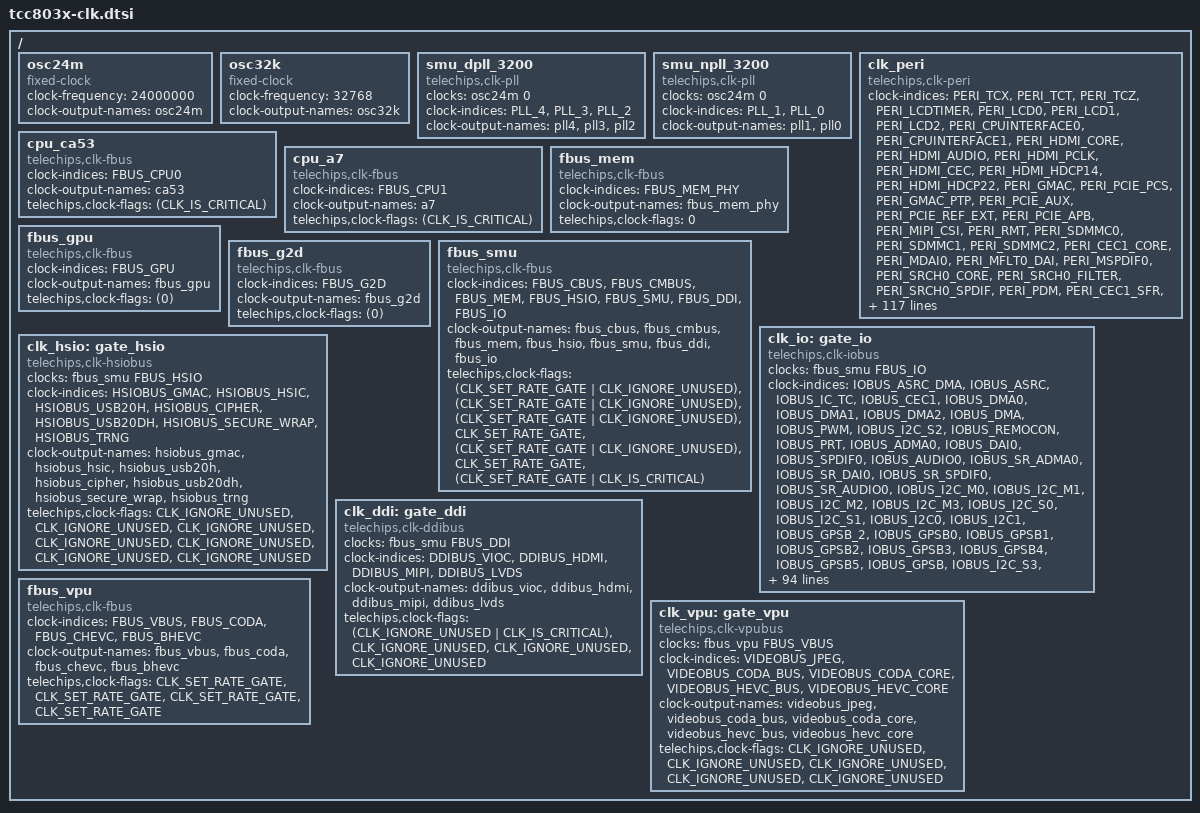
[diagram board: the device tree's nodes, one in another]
// SPDX-License-Identifier: (GPL-2.0-or-later OR MIT)
/*
 * Copyright (C) 2023 Telechips Inc.
 */

#include <dt-bindings/clock/telechips,tcc803x-clks.h>

/ {
	osc24m: osc24m {
		compatible = "fixed-clock";
		#clock-cells = <1>;
		clock-frequency = <24000000>;
		clock-output-names = "osc24m";
	};

	osc32k: osc32k {
		compatible = "fixed-clock";
		#clock-cells = <1>;
		clock-frequency = <32768>;
		clock-output-names = "osc32k";
	};

	smu_dpll_3200: smu_dpll_3200 {
		compatible = "telechips,clk-pll";
		#clock-cells = <1>;
		clocks = <&osc24m 0>;
		clock-indices = <PLL_4>, <PLL_3>, <PLL_2>;
		clock-output-names = "pll4", "pll3", "pll2";
	};

	smu_npll_3200: smu_npll_3200 {
		compatible = "telechips,clk-pll";
		#clock-cells = <1>;
		clocks = <&osc24m 0>;
		clock-indices = <PLL_1>, <PLL_0>;
		clock-output-names = "pll1", "pll0";
	};

	clk_peri: clk_peri {
		compatible = "telechips,clk-peri";
		#clock-cells = <1>;
		clock-indices =
			<PERI_TCX>, <PERI_TCT>, <PERI_TCZ>,
			<PERI_LCDTIMER>, <PERI_LCD0>, <PERI_LCD1>,
			<PERI_LCD2>, <PERI_CPUINTERFACE0>,
			<PERI_CPUINTERFACE1>, <PERI_HDMI_CORE>,
			<PERI_HDMI_AUDIO>, <PERI_HDMI_PCLK>,
			<PERI_HDMI_CEC>, <PERI_HDMI_HDCP14>,
			<PERI_HDMI_HDCP22>, <PERI_GMAC>,
			<PERI_PCIE_PCS>, <PERI_GMAC_PTP>,
			<PERI_PCIE_AUX>, <PERI_PCIE_REF_EXT>,
			<PERI_PCIE_APB>, <PERI_MIPI_CSI>, <PERI_RMT>,
			<PERI_SDMMC0>, <PERI_SDMMC1>, <PERI_SDMMC2>,
			<PERI_CEC1_CORE>, <PERI_MDAI0>, <PERI_MFLT0_DAI>,
			<PERI_MSPDIF0>, <PERI_SRCH0_CORE>,
			<PERI_SRCH0_FILTER>, <PERI_SRCH0_SPDIF>,
			<PERI_PDM>, <PERI_CEC1_SFR>, <PERI_TSADC>,
			<PERI_I2C0>, <PERI_I2C1>, <PERI_I2C2>, <PERI_I2C3>,
			<PERI_UART0>, <PERI_UART1>, <PERI_UART2>,
			<PERI_UART3>, <PERI_MDAI1>, <PERI_MFLT1_DAI>,
			<PERI_MSPDIF1>, <PERI_MDAI2>, <PERI_GPSB0>,
			<PERI_GPSB1>, <PERI_GPSB2>, <PERI_GPSBMS0>,
			<PERI_GPSBMS1>, <PERI_GPSBMS2>, <PERI_UART4>,
			<PERI_AUX0_INPUT>, <PERI_AUX1_INPUT>,
			<PERI_MFLT2_DAI>, <PERI_AUX0_OUTPUT>,
			<PERI_AUX1_OUTPUT>, <PERI_MSPDIF2>, <PERI_IC_TC>,
			<PERI_SRCH1_CORE>, <PERI_SRCH1_FILTER>,
			<PERI_SRCH1_SPDIF>, <PERI_SRCH2_CORE>,
			<PERI_SRCH2_FILTER>, <PERI_SRCH2_SPDIF>,
			<PERI_SRCH3_CORE>, <PERI_SRCH3_FILTER>,
			<PERI_SRCH3_SPDIF>, <PERI_TSRX0>, <PERI_TSRX1>,
			<PERI_TSRX2>, <PERI_TSRX3>, <PERI_TSRX4>,
			<PERI_TSRX5>, <PERI_TSRX6>, <PERI_TSRX7>,
			<PERI_TSRX8>, <PERI_CB_WDT>, <PERI_LVDS_PHY>,
			<PERI_OUT0>, <PERI_OUT1>, <PERI_OUT2>, <PERI_OUT3>,
			<PERI_OUT4>, <PERI_OUT5>;
		clock-output-names =
			"peri_tcx", "peri_tct", "peri_tcz",
			"peri_lcdtimer", "peri_lcd0", "peri_lcd1",
			"peri_lcd2", "peri_cpuinterface0",
			"peri_cpuinterface1", "peri_hdmi_core",
			"peri_hdmi_audio", "peri_hdmi_pclk",
			"peri_hdmi_cec", "peri_hdmi_hdcp14",
			"peri_hdmi_hdcp22", "peri_gmac",
			"peri_pcie_pcs", "peri_gmac_ptp",
			"peri_pcie_aux", "peri_pcie_ref_ext",
			"peri_pcie_apb", "peri_mipi_csi", "peri_rmt",
			"peri_sdmmc0", "peri_sdmmc1", "peri_sdmmc2",
			"peri_cec1_core", "peri_mdai0", "peri_mflt0_dai",
			"peri_mspdif0", "peri_srch0_core",
			"peri_srch0_filter", "peri_srch0_spdif",
			"peri_pdm", "peri_cec1_sfr", "peri_tsadc",
			"peri_i2c0", "peri_i2c1", "peri_i2c2", "peri_i2c3",
			"peri_uart0", "peri_uart1", "peri_uart2",
			"peri_uart3", "peri_mdai1", "peri_mflt1_dai",
			"peri_mspdif1", "peri_mdai2", "peri_gpsb0",
			"peri_gpsb1", "peri_gpsb2", "peri_gpsbms0",
			"peri_gpsbms1", "peri_gpsbms2", "peri_uart4",
			"peri_aux0_input", "peri_aux1_input",
			"peri_mflt2_dai", "peri_aux0_output",
			"peri_aux1_output", "peri_mspdif2", "peri_ic_tc",
			"peri_srch1_core", "peri_srch1_filter",
			"peri_srch1_spdif", "peri_srch2_core",
			"peri_srch2_filter", "peri_srch2_spdif",
			"peri_srch3_core", "peri_srch3_filter",
			"peri_srch3_spdif", "peri_tsrx0", "peri_tsrx1",
			"peri_tsrx2", "peri_tsrx3", "peri_tsrx4",
			"peri_tsrx5", "peri_tsrx6", "peri_tsrx7",
			"peri_tsrx8", "peri_cb_wdt", "peri_lvds_phy",
			"peri_out0", "peri_out1", "peri_out2", "peri_out3",
			"peri_out4", "peri_out5";
		telechips,clock-flags =
			<CLK_IGNORE_UNUSED>,	/* PERI_TCX */
			<CLK_IGNORE_UNUSED>,	/* PERI_TCT */
			<CLK_IGNORE_UNUSED>,	/* PERI_TCZ */
			<CLK_IGNORE_UNUSED>,	/* PERI_LCDTIMER */
			<CLK_IGNORE_UNUSED>,	/* PERI_LCD0 */
			<CLK_IGNORE_UNUSED>,	/* PERI_LCD1 */
			<CLK_IGNORE_UNUSED>,	/* PERI_LCD2 */
			<CLK_IGNORE_UNUSED>,	/* PERI_CPUINTERFACE0 */
			<CLK_IGNORE_UNUSED>,	/* PERI_CPUINTERFACE1 */
			<CLK_IGNORE_UNUSED>,	/* PERI_HDMI_CORE */
			<CLK_IGNORE_UNUSED>,	/* PERI_HDMI_AUDIO */
			<CLK_IGNORE_UNUSED>,	/* PERI_HDMI_PCLK */
			<CLK_IGNORE_UNUSED>,	/* PERI_HDMI_CEC */
			<CLK_IGNORE_UNUSED>,	/* PERI_HDMI_HDCP14 */
			<CLK_IGNORE_UNUSED>,	/* PERI_HDMI_HDCP22 */
			<CLK_IGNORE_UNUSED>,	/* PERI_GMAC */
			<CLK_IGNORE_UNUSED>,	/* PERI_PCIE_PCS */
			<CLK_IGNORE_UNUSED>,	/* PERI_GMAC_PTP */
			<CLK_IGNORE_UNUSED>,	/* PERI_PCIE_AUX */
			<CLK_IGNORE_UNUSED>,	/* PERI_PCIE_REF_EXT */
			<CLK_IGNORE_UNUSED>,	/* PERI_PCIE_APB */
			<CLK_IGNORE_UNUSED>,	/* PERI_MIPI_CSI */
			<CLK_IGNORE_UNUSED>,	/* PERI_RMT */
			<CLK_IGNORE_UNUSED>,	/* PERI_SDMMC0 */
			<CLK_IGNORE_UNUSED>,	/* PERI_SDMMC1 */
			<CLK_IGNORE_UNUSED>,	/* PERI_SDMMC2 */
			<CLK_IGNORE_UNUSED>,	/* PERI_CEC1_CORE */
			<(CLK_IGNORE_UNUSED | CLK_IS_PCLKDCO)>,	/* PERI_MDAI0 */
			<CLK_IGNORE_UNUSED>,	/* PERI_MFLT0_DAI */
			<(CLK_IGNORE_UNUSED | CLK_IS_PCLKDCO)>,	/* PERI_MSPDIF0 */
			<(CLK_IGNORE_UNUSED | CLK_IS_PCLKDCO)>,	/* PERI_SRCH0_CORE */
			<CLK_IGNORE_UNUSED>,	/* PERI_SRCH0_FILTER */
			<(CLK_IGNORE_UNUSED | CLK_IS_PCLKDCO)>,	/* PERI_SRCH0_SPDIF */
			<CLK_IGNORE_UNUSED>,	/* PERI_PDM */
			<CLK_IGNORE_UNUSED>,	/* PERI_CEC1_SFR */
			<CLK_IGNORE_UNUSED>,	/* PERI_TSADC */
			<CLK_IGNORE_UNUSED>,	/* PERI_I2C0 */
			<CLK_IGNORE_UNUSED>,	/* PERI_I2C1 */
			<CLK_IGNORE_UNUSED>,	/* PERI_I2C2 */
			<CLK_IGNORE_UNUSED>,	/* PERI_I2C3 */
			<CLK_IGNORE_UNUSED>,	/* PERI_UART0 */
			<CLK_IGNORE_UNUSED>,	/* PERI_UART1 */
			<CLK_IGNORE_UNUSED>,	/* PERI_UART2 */
			<CLK_IGNORE_UNUSED>,	/* PERI_UART3 */
			<(CLK_IGNORE_UNUSED | CLK_IS_PCLKDCO)>,	/* PERI_MDAI1 */
			<CLK_IGNORE_UNUSED>,	/* PERI_MFLT1_DAI */
			<(CLK_IGNORE_UNUSED | CLK_IS_PCLKDCO)>,	/* PERI_MSPDIF1 */
			<(CLK_IGNORE_UNUSED | CLK_IS_PCLKDCO)>,	/* PERI_MDAI2 */
			<CLK_IGNORE_UNUSED>,	/* PERI_GPSB0 */
			<CLK_IGNORE_UNUSED>,	/* PERI_GPSB1 */
			<CLK_IGNORE_UNUSED>,	/* PERI_GPSB2 */
			<CLK_IGNORE_UNUSED>,	/* PERI_GPSBMS0 */
			<CLK_IGNORE_UNUSED>,	/* PERI_GPSBMS1 */
			<CLK_IGNORE_UNUSED>,	/* PERI_GPSBMS2 */
			<CLK_IGNORE_UNUSED>,	/* PERI_UART4 */
			<(CLK_IGNORE_UNUSED | CLK_IS_PCLKDCO)>,	/* PERI_AUX0_INPUT */
			<(CLK_IGNORE_UNUSED | CLK_IS_PCLKDCO)>,	/* PERI_AUX1_INPUT */
			<CLK_IGNORE_UNUSED>,	/* PERI_MFLT2_DAI */
			<(CLK_IGNORE_UNUSED | CLK_IS_PCLKDCO)>,	/* PERI_AUX0_OUTPUT */
			<(CLK_IGNORE_UNUSED | CLK_IS_PCLKDCO)>,	/* PERI_AUX1_OUTPUT */
			<(CLK_IGNORE_UNUSED | CLK_IS_PCLKDCO)>,	/* PERI_MSPDIF2 */
			<CLK_IGNORE_UNUSED>,	/* PERI_IC_TC */
			<(CLK_IGNORE_UNUSED | CLK_IS_PCLKDCO)>,	/* PERI_SRCH1_CORE */
			<CLK_IGNORE_UNUSED>,	/* PERI_SRCH1_FILTER */
			<(CLK_IGNORE_UNUSED | CLK_IS_PCLKDCO)>,	/* PERI_SRCH1_SPDIF */
			<(CLK_IGNORE_UNUSED | CLK_IS_PCLKDCO)>,	/* PERI_SRCH2_CORE */
			<CLK_IGNORE_UNUSED>,	/* PERI_SRCH2_FILTER */
			<(CLK_IGNORE_UNUSED | CLK_IS_PCLKDCO)>,	/* PERI_SRCH2_SPDIF */
			<(CLK_IGNORE_UNUSED | CLK_IS_PCLKDCO)>,	/* PERI_SRCH3_CORE */
			<CLK_IGNORE_UNUSED>,	/* PERI_SRCH3_FILTER */
			<(CLK_IGNORE_UNUSED | CLK_IS_PCLKDCO)>,	/* PERI_SRCH3_SPDIF */
			<(CLK_IGNORE_UNUSED | CLK_IS_PCLKDCO)>,	/* PERI_TSRX0 */
			<(CLK_IGNORE_UNUSED | CLK_IS_PCLKDCO)>,	/* PERI_TSRX1 */
			<(CLK_IGNORE_UNUSED | CLK_IS_PCLKDCO)>,	/* PERI_TSRX2 */
			<(CLK_IGNORE_UNUSED | CLK_IS_PCLKDCO)>,	/* PERI_TSRX3 */
			<(CLK_IGNORE_UNUSED | CLK_IS_PCLKDCO)>,	/* PERI_TSRX4 */
			<(CLK_IGNORE_UNUSED | CLK_IS_PCLKDCO)>,	/* PERI_TSRX5 */
			<(CLK_IGNORE_UNUSED | CLK_IS_PCLKDCO)>,	/* PERI_TSRX6 */
			<(CLK_IGNORE_UNUSED | CLK_IS_PCLKDCO)>,	/* PERI_TSRX7 */
			<(CLK_IGNORE_UNUSED | CLK_IS_PCLKDCO)>,	/* PERI_TSRX8 */
			<CLK_IGNORE_UNUSED>,	/* PERI_CB_WDT */
			<CLK_IGNORE_UNUSED>,	/* PERI_LVDS_PHY */
			<CLK_IGNORE_UNUSED>,	/* PERI_OUT0 */
			<CLK_IGNORE_UNUSED>,	/* PERI_OUT1 */
			<CLK_IGNORE_UNUSED>,	/* PERI_OUT2 */
			<CLK_IGNORE_UNUSED>,	/* PERI_OUT3 */
			<CLK_IGNORE_UNUSED>,	/* PERI_OUT4 */
			<CLK_IGNORE_UNUSED>;	/* PERI_OUT5 */
	};

	cpu_ca53: cpu_ca53 {
		compatible = "telechips,clk-fbus";
		#clock-cells = <1>;
		clock-indices = <FBUS_CPU0>;
		clock-output-names = "ca53";
		telechips,clock-flags = <(CLK_IS_CRITICAL)>;
	};

	cpu_a7: cpu_a7 {
		compatible = "telechips,clk-fbus";
		#clock-cells = <1>;
		clock-indices = <FBUS_CPU1>;
		clock-output-names = "a7";
		telechips,clock-flags = <(CLK_IS_CRITICAL)>;
	};

	fbus_mem: fbus_mem {
		compatible = "telechips,clk-fbus";
		#clock-cells = <1>;
		clock-indices = <FBUS_MEM_PHY>;
		clock-output-names = "fbus_mem_phy";
		telechips,clock-flags = <0>;	/* FBUS_MEM_PHY */
	};

	fbus_gpu: fbus_gpu {
		compatible = "telechips,clk-fbus";
		#clock-cells = <1>;
		clock-indices = <FBUS_GPU>;
		clock-output-names = "fbus_gpu";
		telechips,clock-flags = <(0)>;
	};

	fbus_g2d: fbus_g2d {
		compatible = "telechips,clk-fbus";
		#clock-cells = <1>;
		clock-indices = <FBUS_G2D>;
		clock-output-names = "fbus_g2d";
		telechips,clock-flags = <(0)>;
	};

	fbus_smu: fbus_smu {
		compatible = "telechips,clk-fbus";
		#clock-cells = <1>;
		clock-indices =
			<FBUS_CBUS>, <FBUS_CMBUS>, <FBUS_MEM>,
			<FBUS_HSIO>, <FBUS_SMU>, <FBUS_DDI>,
			<FBUS_IO>;
		clock-output-names =
			"fbus_cbus", "fbus_cmbus", "fbus_mem",
			"fbus_hsio", "fbus_smu", "fbus_ddi",
			"fbus_io";
		telechips,clock-flags =
			<(CLK_SET_RATE_GATE | CLK_IGNORE_UNUSED)>,	/* FBUS_CBUS */
			<(CLK_SET_RATE_GATE | CLK_IGNORE_UNUSED)>,	/* FBUS_CMBUS */
			<(CLK_SET_RATE_GATE | CLK_IGNORE_UNUSED)>,	/* FBUS_MEM */
			<CLK_SET_RATE_GATE>,	/* FBUS_HSIO */
			<(CLK_SET_RATE_GATE | CLK_IGNORE_UNUSED)>,	/* FBUS_SMU */
			<CLK_SET_RATE_GATE>,	/* FBUS_DDI */
			<(CLK_SET_RATE_GATE | CLK_IS_CRITICAL)>;	/* FBUS_IO */
	};

	clk_io: gate_io {
		compatible = "telechips,clk-iobus";
		#clock-cells = <1>;
		clocks = <&fbus_smu FBUS_IO>;
		clock-indices =
			<IOBUS_ASRC_DMA>, <IOBUS_ASRC>, <IOBUS_IC_TC>,
			<IOBUS_CEC1>, <IOBUS_DMA0>, <IOBUS_DMA1>,
			<IOBUS_DMA2>, <IOBUS_DMA>, <IOBUS_PWM>,
			<IOBUS_I2C_S2>, <IOBUS_REMOCON>, <IOBUS_PRT>,
			<IOBUS_ADMA0>, <IOBUS_DAI0>, <IOBUS_SPDIF0>,
			<IOBUS_AUDIO0>, <IOBUS_SR_ADMA0>,
			<IOBUS_SR_DAI0>, <IOBUS_SR_SPDIF0>,
			<IOBUS_SR_AUDIO0>, <IOBUS_I2C_M0>,
			<IOBUS_I2C_M1>, <IOBUS_I2C_M2>, <IOBUS_I2C_M3>,
			<IOBUS_I2C_S0>, <IOBUS_I2C_S1>, <IOBUS_I2C0>,
			<IOBUS_I2C1>, <IOBUS_GPSB_2>, <IOBUS_GPSB0>,
			<IOBUS_GPSB1>, <IOBUS_GPSB2>, <IOBUS_GPSB3>,
			<IOBUS_GPSB4>, <IOBUS_GPSB5>, <IOBUS_GPSB>,
			<IOBUS_I2C_S3>, <IOBUS_I2C_M4>, <IOBUS_I2C_M5>,
			<IOBUS_I2C_M6>, <IOBUS_I2C_M7>, <IOBUS_UART0>,
			<IOBUS_UART1>, <IOBUS_UART2>, <IOBUS_UART3>,
			<IOBUS_UART4>, <IOBUS_SMARTCARD4>, <IOBUS_UDMA0>,
			<IOBUS_UDMA1>, <IOBUS_UDMA2>, <IOBUS_UDMA3>,
			<IOBUS_UART_SMARTCARD0>,
			<IOBUS_UART_SMARTCARD1>, <IOBUS_ADMA1>, <IOBUS_DAI1>,
			<IOBUS_SPDIF1>, <IOBUS_AUDIO1>, <IOBUS_ADMA2>,
			<IOBUS_DAI2>, <IOBUS_SPDIF2>, <IOBUS_AUDIO2>,
			<IOBUS_SR_ADMA1>, <IOBUS_SR_DAI1>,
			<IOBUS_SR_SPDIF1>, <IOBUS_SR_AUDIO1>,
			<IOBUS_SR_ADMA2>, <IOBUS_SR_DAI2>,
			<IOBUS_SR_SPDIF2>, <IOBUS_SR_AUDIO2>,
			<IOBUS_SR_ADMA3>, <IOBUS_SR_DAI3>,
			<IOBUS_SR_SPDIF3>, <IOBUS_SR_AUDIO3>, <IOBUS_GDMA1>,
			<IOBUS_CIPHER>, <IOBUS_SDMMC0>, <IOBUS_SDMMC1>,
			<IOBUS_SDMMC2>, <IOBUS_SDMMC>, <IOBUS_SMC>,
			<IOBUS_NFC>, <IOBUS_EDICFG>, <IOBUS_EDI>,
			<IOBUS_RTC>;
		clock-output-names =
			"iobus_asrc_dma", "iobus_asrc", "iobus_ic_tc",
			"iobus_cec1", "iobus_dma0", "iobus_dma1",
			"iobus_dma2", "iobus_dma", "iobus_pwm",
			"iobus_i2c_s2", "iobus_remocon", "iobus_prt",
			"iobus_adma0", "iobus_dai0", "iobus_spdif0",
			"iobus_audio0", "iobus_sr_adma0",
			"iobus_sr_dai0", "iobus_sr_spdif0",
			"iobus_sr_audio0", "iobus_i2c_m0",
			"iobus_i2c_m1", "iobus_i2c_m2", "iobus_i2c_m3",
			"iobus_i2c_s0", "iobus_i2c_s1", "iobus_i2c0",
			"iobus_i2c1", "iobus_gpsb_2", "iobus_gpsb0",
			"iobus_gpsb1", "iobus_gpsb2", "iobus_gpsb3",
			"iobus_gpsb4", "iobus_gpsb5", "iobus_gpsb",
			"iobus_i2c_s3", "iobus_i2c_m4", "iobus_i2c_m5",
			"iobus_i2c_m6", "iobus_i2c_m7", "iobus_uart0",
			"iobus_uart1", "iobus_uart2", "iobus_uart3",
			"iobus_uart4", "iobus_smartcard4", "iobus_udma0",
			"iobus_udma1", "iobus_udma2", "iobus_udma3",
			"iobus_uart_smartcard0",
			"iobus_uart_smartcard1", "iobus_adma1", "iobus_dai1",
			"iobus_spdif1", "iobus_audio1", "iobus_adma2",
			"iobus_dai2", "iobus_spdif2", "iobus_audio2",
			"iobus_sr_adma1", "iobus_sr_dai1",
			"iobus_sr_spdif1", "iobus_sr_audio1",
			"iobus_sr_adma2", "iobus_sr_dai2",
			"iobus_sr_spdif2", "iobus_sr_audio2",
			"iobus_sr_adma3", "iobus_sr_dai3",
			"iobus_sr_spdif3", "iobus_sr_audio3", "iobus_gdma1",
			"iobus_cipher", "iobus_sdmmc0", "iobus_sdmmc1",
			"iobus_sdmmc2", "iobus_sdmmc", "iobus_smc",
			"iobus_nfc", "iobus_edicfg", "iobus_edi",
			"iobus_rtc";
		telechips,clock-flags =
			<CLK_IGNORE_UNUSED>,	/* IOBUS_ASRC_DMA */
			<CLK_IGNORE_UNUSED>,	/* IOBUS_ASRC */
			<CLK_IGNORE_UNUSED>,	/* IOBUS_IC_TC */
			<CLK_IGNORE_UNUSED>,	/* IOBUS_CEC1 */
			<CLK_IGNORE_UNUSED>,	/* IOBUS_DMA0 */
			<CLK_IGNORE_UNUSED>,	/* IOBUS_DMA1 */
			<CLK_IGNORE_UNUSED>,	/* IOBUS_DMA2 */
			<CLK_IGNORE_UNUSED>,	/* IOBUS_DMA */
			<CLK_IGNORE_UNUSED>,	/* IOBUS_PWM */
			<CLK_IGNORE_UNUSED>,	/* IOBUS_I2C_S2 */
			<CLK_IGNORE_UNUSED>,	/* IOBUS_REMOCON */
			<CLK_IGNORE_UNUSED>,	/* IOBUS_PRT */
			<CLK_IGNORE_UNUSED>,	/* IOBUS_ADMA0 */
			<CLK_IGNORE_UNUSED>,	/* IOBUS_DAI0 */
			<CLK_IGNORE_UNUSED>,	/* IOBUS_SPDIF0 */
			<CLK_IGNORE_UNUSED>,	/* IOBUS_AUDIO0 */
			<CLK_IGNORE_UNUSED>,	/* IOBUS_SR_ADMA0 */
			<CLK_IGNORE_UNUSED>,	/* IOBUS_SR_DAI0 */
			<CLK_IGNORE_UNUSED>,	/* IOBUS_SR_SPDIF0 */
			<CLK_IGNORE_UNUSED>,	/* IOBUS_SR_AUDIO0 */
			<CLK_IGNORE_UNUSED>,	/* IOBUS_I2C_M0 */
			<CLK_IGNORE_UNUSED>,	/* IOBUS_I2C_M1 */
			<CLK_IGNORE_UNUSED>,	/* IOBUS_I2C_M2 */
			<CLK_IGNORE_UNUSED>,	/* IOBUS_I2C_M3 */
			<CLK_IGNORE_UNUSED>,	/* IOBUS_I2C_S0 */
			<CLK_IGNORE_UNUSED>,	/* IOBUS_I2C_S1 */
			<CLK_IGNORE_UNUSED>,	/* IOBUS_I2C0 */
			<CLK_IGNORE_UNUSED>,	/* IOBUS_I2C1 */
			<CLK_IGNORE_UNUSED>,	/* IOBUS_GPSB_2 */
			<CLK_IGNORE_UNUSED>,	/* IOBUS_GPSB0 */
			<CLK_IGNORE_UNUSED>,	/* IOBUS_GPSB1 */
			<CLK_IGNORE_UNUSED>,	/* IOBUS_GPSB2 */
			<CLK_IGNORE_UNUSED>,	/* IOBUS_GPSB3 */
			<CLK_IGNORE_UNUSED>,	/* IOBUS_GPSB4 */
			<CLK_IGNORE_UNUSED>,	/* IOBUS_GPSB5 */
			<CLK_IGNORE_UNUSED>,	/* IOBUS_GPSB */
			<CLK_IGNORE_UNUSED>,	/* IOBUS_I2C_S3 */
			<CLK_IGNORE_UNUSED>,	/* IOBUS_I2C_M4 */
			<CLK_IGNORE_UNUSED>,	/* IOBUS_I2C_M5 */
			<CLK_IGNORE_UNUSED>,	/* IOBUS_I2C_M6 */
			<CLK_IGNORE_UNUSED>,	/* IOBUS_I2C_M7 */
			<CLK_IGNORE_UNUSED>,	/* IOBUS_UART0 */
			<CLK_IGNORE_UNUSED>,	/* IOBUS_UART1 */
			<CLK_IGNORE_UNUSED>,	/* IOBUS_UART2 */
			<CLK_IGNORE_UNUSED>,	/* IOBUS_UART3 */
			<CLK_IGNORE_UNUSED>,	/* IOBUS_UART4 */
			<CLK_IGNORE_UNUSED>,	/* IOBUS_SMARTCARD4 */
			<CLK_IGNORE_UNUSED>,	/* IOBUS_UDMA0 */
			<CLK_IGNORE_UNUSED>,	/* IOBUS_UDMA1 */
			<CLK_IGNORE_UNUSED>,	/* IOBUS_UDMA2 */
			<CLK_IGNORE_UNUSED>,	/* IOBUS_UDMA3 */
			<CLK_IGNORE_UNUSED>,	/* IOBUS_UART_SMARTCARD0 */
			<CLK_IGNORE_UNUSED>,	/* IOBUS_UART_SMARTCARD1 */
			<CLK_IGNORE_UNUSED>,	/* IOBUS_ADMA1 */
			<CLK_IGNORE_UNUSED>,	/* IOBUS_DAI1 */
			<CLK_IGNORE_UNUSED>,	/* IOBUS_SPDIF1 */
			<CLK_IGNORE_UNUSED>,	/* IOBUS_AUDIO1 */
			<CLK_IGNORE_UNUSED>,	/* IOBUS_ADMA2 */
			<CLK_IGNORE_UNUSED>,	/* IOBUS_DAI2 */
			<CLK_IGNORE_UNUSED>,	/* IOBUS_SPDIF2 */
			<CLK_IGNORE_UNUSED>,	/* IOBUS_AUDIO2 */
			<CLK_IGNORE_UNUSED>,	/* IOBUS_SR_ADMA1 */
			<CLK_IGNORE_UNUSED>,	/* IOBUS_SR_DAI1 */
			<CLK_IGNORE_UNUSED>,	/* IOBUS_SR_SPDIF1 */
			<CLK_IGNORE_UNUSED>,	/* IOBUS_SR_AUDIO1 */
			<CLK_IGNORE_UNUSED>,	/* IOBUS_SR_ADMA2 */
			<CLK_IGNORE_UNUSED>,	/* IOBUS_SR_DAI2 */
			<CLK_IGNORE_UNUSED>,	/* IOBUS_SR_SPDIF2 */
			<CLK_IGNORE_UNUSED>,	/* IOBUS_SR_AUDIO2 */
			<CLK_IGNORE_UNUSED>,	/* IOBUS_SR_ADMA3 */
			<CLK_IGNORE_UNUSED>,	/* IOBUS_SR_DAI3 */
			<CLK_IGNORE_UNUSED>,	/* IOBUS_SR_SPDIF3 */
			<CLK_IGNORE_UNUSED>,	/* IOBUS_SR_AUDIO3 */
			<CLK_IGNORE_UNUSED>,	/* IOBUS_GDMA1 */
			<CLK_IGNORE_UNUSED>,	/* IOBUS_CIPHER */
			<CLK_IGNORE_UNUSED>,	/* IOBUS_SDMMC0 */
			<CLK_IGNORE_UNUSED>,	/* IOBUS_SDMMC1 */
			<CLK_IGNORE_UNUSED>,	/* IOBUS_SDMMC2 */
			<CLK_IGNORE_UNUSED>,	/* IOBUS_SDMMC */
			<CLK_IGNORE_UNUSED>,	/* IOBUS_SMC */
			<CLK_IGNORE_UNUSED>,	/* IOBUS_NFC */
			<CLK_IGNORE_UNUSED>,	/* IOBUS_EDICFG */
			<CLK_IGNORE_UNUSED>,	/* IOBUS_EDI */
			<CLK_IGNORE_UNUSED>;	/* IOBUS_RTC */
	};

	clk_hsio: gate_hsio {
		compatible = "telechips,clk-hsiobus";
		#clock-cells = <1>;
		clocks = <&fbus_smu FBUS_HSIO>;
		clock-indices =
			<HSIOBUS_GMAC>, <HSIOBUS_HSIC>, <HSIOBUS_USB20H>,
			<HSIOBUS_CIPHER>, <HSIOBUS_USB20DH>,
			<HSIOBUS_SECURE_WRAP>, <HSIOBUS_TRNG>;
		clock-output-names =
			"hsiobus_gmac", "hsiobus_hsic", "hsiobus_usb20h",
			"hsiobus_cipher", "hsiobus_usb20dh",
			"hsiobus_secure_wrap", "hsiobus_trng";
		telechips,clock-flags =
			<CLK_IGNORE_UNUSED>,	/* HSIOBUS_GMAC */
			<CLK_IGNORE_UNUSED>,	/* HSIOBUS_HSIC */
			<CLK_IGNORE_UNUSED>,	/* HSIOBUS_USB20H */
			<CLK_IGNORE_UNUSED>,	/* HSIOBUS_CIPHER */
			<CLK_IGNORE_UNUSED>,	/* HSIOBUS_USB20DH */
			<CLK_IGNORE_UNUSED>,	/* HSIOBUS_SECURE_WRAP */
			<CLK_IGNORE_UNUSED>;	/* HSIOBUS_TRNG */
	};

	clk_ddi: gate_ddi {
		compatible = "telechips,clk-ddibus";
		#clock-cells = <1>;
		clocks = <&fbus_smu FBUS_DDI>;
		clock-indices =
			<DDIBUS_VIOC>, <DDIBUS_HDMI>, <DDIBUS_MIPI>,
			<DDIBUS_LVDS>;
		clock-output-names =
			"ddibus_vioc", "ddibus_hdmi", "ddibus_mipi",
			"ddibus_lvds";
		telechips,clock-flags =
			<(CLK_IGNORE_UNUSED | CLK_IS_CRITICAL)>,	/* DDIBUS_VIOC */
			<CLK_IGNORE_UNUSED>,	/* DDIBUS_HDMI */
			<CLK_IGNORE_UNUSED>,	/* DDIBUS_MIPI */
			<CLK_IGNORE_UNUSED>;	/* DDIBUS_LVDS */
	};

	fbus_vpu: fbus_vpu {
		compatible = "telechips,clk-fbus";
		#clock-cells = <1>;
		clock-indices =
			<FBUS_VBUS>,<FBUS_CODA>, <FBUS_CHEVC>, <FBUS_BHEVC>;
		clock-output-names =
			"fbus_vbus","fbus_coda", "fbus_chevc", "fbus_bhevc";
		telechips,clock-flags =
			<CLK_SET_RATE_GATE>,	/* FBUS_VBUS */
			<CLK_SET_RATE_GATE>,	/* FBUS_CODA */
			<CLK_SET_RATE_GATE>,	/* FBUS_CHEVC */
			<CLK_SET_RATE_GATE>;	/* FBUS_BHEVC */
	};

	clk_vpu: gate_vpu {
		compatible = "telechips,clk-vpubus";
		#clock-cells = <1>;
		clocks = <&fbus_vpu FBUS_VBUS>;
		clock-indices =
			<VIDEOBUS_JPEG>, <VIDEOBUS_CODA_BUS>,
			<VIDEOBUS_CODA_CORE>, <VIDEOBUS_HEVC_BUS>,
			<VIDEOBUS_HEVC_CORE>;
		clock-output-names =
			"videobus_jpeg", "videobus_coda_bus",
			"videobus_coda_core", "videobus_hevc_bus",
			"videobus_hevc_core";
		telechips,clock-flags =
			<CLK_IGNORE_UNUSED>,	/* VIDEOBUS_JPEG */
			<CLK_IGNORE_UNUSED>,	/* VIDEOBUS_CODA_BUS */
			<CLK_IGNORE_UNUSED>,	/* VIDEOBUS_CODA_CORE */
			<CLK_IGNORE_UNUSED>,	/* VIDEOBUS_HEVC_BUS */
			<CLK_IGNORE_UNUSED>;	/* VIDEOBUS_HEVC_CORE */
	};
};
